# ESP32S3_RADIO register map
File version: 0.1.0
Registers are 32-bit, read-write, no defined reset value unless marked. A register's access mark holds for its fields unless they carry their own. Offsets are from the block's base; [hi:lo] are bit positions; {n}, {i} and the like mark numbered series.

## ULP — Analog I2C block 0x61 (ULP) One bit of this block takes part in the RC calibration of block 0x6a.
Base 0x00006100
0x08 R8 8-bit — Bit 2 set during the RC time-constant measurement
  [2] R8_B2 — Set for the RC time-constant measurement in `get_rc_dout()`, cleared after (see block 0x6a). Evidence: *decompile* S3 `phy_analog_cal.o`

## RFPLL_SDM — Analog I2C block 0x63 (RF PLL fractional-N divider) The S3 sets the PLL frequency through registers 0 and 3 to 5: `f_PLL = 0.75 * f_xtal * (32 + r3 + r4 / 2^8 + r5 / 2^16)` With the 40 MHz crystal that is 30 MHz per integer step and about 458 Hz per LSB. `write_rfpll_sdm()` writes reg 0 = 0x07, regs 3 to 5, then reg 0 = 0x17 (bit 4 presumably loads the word). | PLL MHz | reg 3 | reg 4 | reg 5 | Decoded | |---|---|---|---|---| | 2412 | 0x30 | 0x66 | 0x66 | 30 MHz x 80.4 | | 2500 | 0x33 | 0x55 | 0x55 | 30 MHz x 83.33 | | 2700 | 0x3a | 0x00 | 0x00 | 30 MHz x 90 | Evidence: *decompile* S3 `phy_rfpll.o` (`rfpll_set_freq()`), S3 `phy_rfpll.o` (`write_rfpll_sdm()`); *measured* bench 2026-10-09: the raw values match the formula exactly. The crystal selector of the vendor calls picks the divisor, as on the C6: 1 = 26 MHz, 2 = 32 MHz, anything else = 40 MHz (*decompile* S3 `phy_rfpll.o`).
Base 0x00006300
0x00 R0 8-bit — Divider word load (presumed)
  [4] LOAD — Presumably loads the word: `write_rfpll_sdm()` writes the register as 0x07 before registers 3 to 5 and as 0x17 after them. Evidence: *decompile* S3 `phy_rfpll.o` (`write_rfpll_sdm()`)
0x03 R3 8-bit — Integer part above 32
  [7:0] INTEGER — `r3` in the formula above: 30 MHz per step with the 40 MHz crystal.
0x04 R4 8-bit — Fraction, high byte
  [7:0] FRAC_H — `r4` in the formula above, weight 1 / 2^8.
0x05 R5 8-bit — Fraction, low byte
  [7:0] FRAC_L — `r5` in the formula above, weight 1 / 2^16: about 458 Hz per LSB with the 40 MHz crystal.

## CKGEN — Analog I2C block 0x65 (clock generator, LO 5/6 divider) Register 0 bit 4 (mask 0x10) selects the LO 5/6 divider. The ESP32-C6 has no block 0x65; its selector is in block 0x62. - The S3 libphy and librftest objects only read block 0x65 in their debug dump (*decompile* S3 `phy_debug.o`). - Upstream qualifies the selector on the ESP32, S2, S3, C2, C3 and C6 and warns that the C5, C61, H2 and S31 lay out their analog blocks differently (`modules/lib/esp-sdr/docs/rx-controls.md:102-107`).
Base 0x00006500
0x00 R0 8-bit — LO 5/6 divider select - Change only the bit (read-modify-write). Clear it before the vendor tuning call, which calibrates in normal mode; set it after the receive or transmit front-end setup. - Without the select on the transmit side, transmissions in the divider band went out at 6/5 of the target. - The library uses the divider for every frequency below 2210 MHz (PLL at 1.2 times the LO), upstream only from 1842 MHz. Evidence: *working* `lib/esp_sdr/src/esp_sdr.c:106-108`, `lib/esp_sdr/src/esp_sdr_rx.c:92-95`, `lib/esp_sdr/src/esp_sdr_tx.c:25-26, 77-83` (read-modify-write and order) Evidence: *measured* bench 2026-10-09 (6/5 of the target on transmit) Evidence: `lib/esp_sdr/src/esp_sdr.c:65-76`, `modules/lib/esp-sdr/main/common/rx_lo.h:15-19` (divider band)
  [4] LO_DIV — 0: the LO is the PLL. 1: LO = PLL / 1.2 (5/6 conversion). One selector feeds both the receive and the transmit mixer. Evidence: *upstream* `modules/lib/esp-sdr/main/common/rx_lo.h:47-62`, external-tone tests `modules/lib/esp-sdr/docs/rx-controls.md:76-100`; *measured* on air for receive and transmit (bench 2026-10-09)

## BBTOP — Analog I2C block 0x67 (BBTOP, analog baseband) esp_sdr writes the receive and transmit filter codes here. - BBTOP_R4 and BBTOP_R6 both reading 0x10 is the vendor's sign that BBTOP lost its state; it then reruns its init (*decompile* S3 `phy_i2c.o`). - Writing the other pairs (0x06/0x07 up to 0x1e/0x1f) disturbed reception until a reboot (*measured* bench 2026-10-06). `esp_sdr_bbtop_read()` and `esp_sdr_bbtop_write()` give unchecked access (`lib/esp_sdr/src/esp_sdr_rx.c:648-667`). - The PHY's channel bandwidth mode changes these filters too (hardware-quirks.md, "40 MHz mode widens the analog filters"). Registers 0x24 to 0x38 (36 to 56) take init constants, bits 7:0 (*decompile* S3 `phy_i2c.o`): | Registers | Value | |---|---| | 0x24, 0x28 | 0x48 | | 0x25, 0x29 | 0x08 | | 0x2c, 0x2d, 0x30, 0x31 | 0x88 | | 0x34, 0x35 | 0x11 | | 0x38 | 0xff |
Base 0x00006700
0x02 R2 8-bit — Unknown 2-bit field, 1 at init `phy_close_rf()` writes the register as 6. Evidence: *decompile* S3 `phy_i2c.o`, `phy_init.o`
  [3:2] R2_B3_2 — Unknown; 1 at init.
0x03 R3 8-bit — Unknown bit, changed by the receive calibration The S3 frequency hop engine (see "Analog I2C master") writes the register as 0xf0 and 0xf4. Evidence: *speculative* S3 `phy_rx_cal.o`, `phy_hw_freq.o`
  [2] R3_B2 — Unknown; saved, changed and restored by the receive calibration.
{0x0+i} R{i} (i=4..5) 8-bit — Receive low-pass capacitor code, I (BBTOP_R4) and Q (BBTOP_R5) Vendor scaling: the corner goes as 1 / (code + 8). `phy_rx_band_set(1, bw)` writes `clamp((base + 8) * 19 / min(bw, 19) - 8, 2, 60)` to both; `base` comes from the RC calibration (block 0x6a). Evidence: *decompile* S3 `phy_api.o` (vendor scaling)
  [5:0] RX_LPF — Receive low-pass capacitor code, 0 to 63. Larger is narrower; 0 is the widest setting, not a bypass: about 69 MHz (0) to 13 MHz (60) two-sided, PHY default about 22 MHz. Bits 7:6 are kept. Evidence: *working* `lib/esp_sdr/src/esp_sdr_rx.c:126-148`; *upstream* curves `modules/lib/esp-sdr/main/common/rx_bandwidth.h:79-84`; *measured* (S3 default) bench 2026-10-05
{0x0+i} R{i} (i=6..7) 8-bit — Second capacitor pair, unknown Probably a second receive stage. Written at init and, with BBTOP_R14 and BBTOP_R15 (0x0e, 0x0f), for 10 and 5 MHz channels. The library leaves it alone. Evidence: *speculative*; *decompile* S3 `phy_i2c.o`, `phy_feature.o`
  [5:0] CAP2 — Capacitor code, unknown.
{0x0+i} R{i} (i=12..13) 8-bit — Transmit low-pass pair A (0x0c, 0x0d)
  [5:0] TX_LPF_A — Transmit low-pass code, pair A. 63 narrows TX to about +-6 MHz; codes below the calibrated one (about 35) do not widen it. Evidence: *measured* bench 2026-10-06; *decompile* S3 `rf_test.o`
{0x0+i} R{i} (i=14..15) 8-bit — Transmit low-pass pair B (0x0e, 0x0f)
  [5:0] TX_LPF_B — Transmit low-pass code, pair B. Evidence: *decompile* S3 `rf_test.o`; *working* `lib/esp_sdr/src/esp_sdr_rx.c:578-637`
{0x0+i} R{i} (i=20..23) 8-bit — Unknown pairs (0x14 to 0x17), written from PHY parameters at init Evidence: *speculative* S3 `phy_i2c.o`
  [5:0] B5_0
{0x0+i} R{i} (i=28..31) 8-bit — Unknown pairs (0x1c to 0x1f), written from PHY parameters at init Stepped with BBTOP_R12 and BBTOP_R13 (0x0c, 0x0d) in a TX DC calibration test. Evidence: *speculative* S3 `phy_i2c.o`, `phy_test.o`
  [5:0] B5_0

## BIAS — Analog I2C block 0x6a (bias): RC calibration Not used by esp_sdr. `get_rc_dout(mode)` measures an on-chip RC time constant: it writes `0x6a:2[6:5]` = 2, `0x6a:6[4:0]` = 2, `0x6a:4[7:4]` = 7, 11 or 6 by mode, `0x61:8[2]` = 1 and `0x6a:4[0]` = 1, pulses `0x6a:4[3]`, waits 100 us, reads `0x6a:5[5:0]` and clears `0x61:8[2]` and `0x6a:4[0]`. `rc_cal()` turns the result into the receive filter base code, `clamp((dout + 56) * 82 / 190 - 8, 2, 63)`, so the filter codes follow process spread. Evidence: *decompile* S3 `phy_analog_cal.o`.
Base 0x00006A00
0x02 R2 8-bit — RC measurement setting in bits 6:5 Evidence: *decompile* S3 `phy_analog_cal.o`
  [6:5] R2_B6_5 — Unknown; `get_rc_dout()` writes 2.
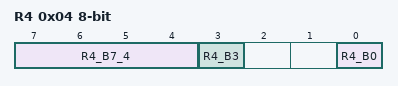
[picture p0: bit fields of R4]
0x04 R4 8-bit — RC measurement mode and control bits Evidence: *decompile* S3 `phy_analog_cal.o`
  [7:4] R4_B7_4 — `get_rc_dout(mode)` writes 7, 11 or 6 by mode.
  [3] R4_B3 wo — Pulsed by `get_rc_dout()`, which then waits 100 us and reads BIAS_RC_DOUT.
  [0] R4_B0 — Set by `get_rc_dout()` before the pulse on BIAS_R4_B3, cleared after the read.
0x05 R5 8-bit — RC measurement result Evidence: *decompile* S3 `phy_analog_cal.o`
  [5:0] RC_DOUT ro — The RC time-constant measurement, read by `get_rc_dout()` 100 us after the pulse on BIAS_R4_B3; `rc_cal()` turns it into the receive filter base code.
0x06 R6 8-bit — RC measurement setting in bits 4:0 Evidence: *decompile* S3 `phy_analog_cal.o`
  [4:0] R6_B4_0 — Unknown; `get_rc_dout()` writes 2.
